AUTOSAR XML (schema 4.0)
standard types defined: float32, float64, sint16, sint32, sint8, uint16, uint32, uint8, void, boolean
package /ImplDataTypes
  4 x impl type, all with category=TYPE_REFERENCE, implementation-data-type=uint8, type-emitter=RTE:
    HeightImpType
    InclineImpType
    MultiStateBtnType
    SlideImpType
package /MappingSets
  data type mapping set MappingSet
package /PortInterfaces/SenderReceiver
  sender receiver interface SrIf_SeatCtrlBtns
    data HeightBtnState: type=MultiStateBtnType
    data InclineBtnState: type=MultiStateBtnType
    data SlideBtnState: type=MultiStateBtnType
  sender receiver interface SrIf_SeatCtrlData
    data Height: type=HeightImpType
    data Incline: type=InclineImpType
    data Slide: type=SlideImpType
package /SoftwareComponents
  application sw component type ECU
    provide port ppSeatCtrlData: provided-interface=SrIf_SeatCtrlData
    behavior Ibhv_ECU: data-type-mapping=MappingSet, handle-termination-and-restart=NO-SUPPORT
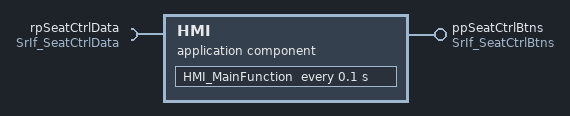
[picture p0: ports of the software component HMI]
  application sw component type HMI
    provide port ppSeatCtrlBtns: provided-interface=SrIf_SeatCtrlBtns
    require port rpSeatCtrlData: required-interface=SrIf_SeatCtrlData
    behavior Ibhv_HMI: data-type-mapping=MappingSet, handle-termination-and-restart=NO-SUPPORT
      timing event TE_HMI_MainFunction_100ms: start-on-event=HMI_MainFunction, period=0.1
      runnable HMI_MainFunction
        data-receive-point-by-arguments:
          access DRP_rpSeatCtrlData_Height: accessed-variable=rpSeatCtrlData.Height
          access DRP_rpSeatCtrlData_Incline: accessed-variable=rpSeatCtrlData.Incline
          access DRP_rpSeatCtrlData_Slide: accessed-variable=rpSeatCtrlData.Slide
        data-send-points:
          access DSP_ppSeatCtrlBtns_HeightBtnState: accessed-variable=ppSeatCtrlBtns.HeightBtnState
          access DSP_ppSeatCtrlBtns_InclineBtnState: accessed-variable=ppSeatCtrlBtns.InclineBtnState
          access DSP_ppSeatCtrlBtns_SlideBtnState: accessed-variable=ppSeatCtrlBtns.SlideBtnState
  swc implementation Impl_ECU: programming-language=C, sw-version=1.0.0, vendor-id=255, behavior=Ibhv_ECU
    code-descriptors:
      code Code: artifact-descriptors=autosar-engineering-object={short-label=SWC.c, category=SWSRC}
    resource consumption ResourceConsumption
  swc implementation Impl_HMI: programming-language=C, sw-version=1.0.0, vendor-id=255, behavior=Ibhv_HMI
    code-descriptors:
      code Code: artifact-descriptors=autosar-engineering-object={short-label=SWC.c, category=SWSRC}
    resource consumption ResourceConsumption
  swc implementation Impl_SeatMgr: programming-language=C, sw-version=1.0.0, vendor-id=255, behavior=Ibhv_SeatMgr
    code-descriptors:
      code Code: artifact-descriptors=autosar-engineering-object={short-label=SWC.c, category=SWSRC}
    resource consumption ResourceConsumption
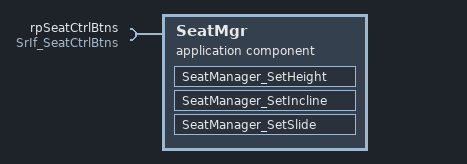
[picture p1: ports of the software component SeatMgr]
  application sw component type SeatMgr
    require port rpSeatCtrlBtns: required-interface=SrIf_SeatCtrlBtns
    behavior Ibhv_SeatMgr: data-type-mapping=MappingSet, handle-termination-and-restart=NO-SUPPORT
      data received event DRE_rpSeatCtrlBtns_HeightBtnState: start-on-event=SeatManager_SetHeight, data=rpSeatCtrlBtns.HeightBtnState
      data received event DRE_rpSeatCtrlBtns_InclineBtnState: start-on-event=SeatManager_SetIncline, data=rpSeatCtrlBtns.InclineBtnState
      data received event DRE_rpSeatCtrlBtns_SlideBtnState: start-on-event=SeatManager_SetSlide, data=rpSeatCtrlBtns.SlideBtnState
      runnable SeatManager_SetHeight
        data-receive-point-by-arguments:
          access DRP_rpSeatCtrlBtns_HeightBtnState: accessed-variable=rpSeatCtrlBtns.HeightBtnState
      runnable SeatManager_SetIncline
        data-receive-point-by-arguments:
          access DRP_rpSeatCtrlBtns_InclineBtnState: accessed-variable=rpSeatCtrlBtns.InclineBtnState
      runnable SeatManager_SetSlide
        data-receive-point-by-arguments:
          access DRP_rpSeatCtrlBtns_SlideBtnState: accessed-variable=rpSeatCtrlBtns.SlideBtnState
package /Compositions
  composition sw component type SR in SeatComposition
    component ECU: type=ECU
    component HMI: type=HMI
    component SeatMgr: type=SeatMgr
    connect HMI.ppSeatCtrlBtns -> SeatMgr.rpSeatCtrlBtns
